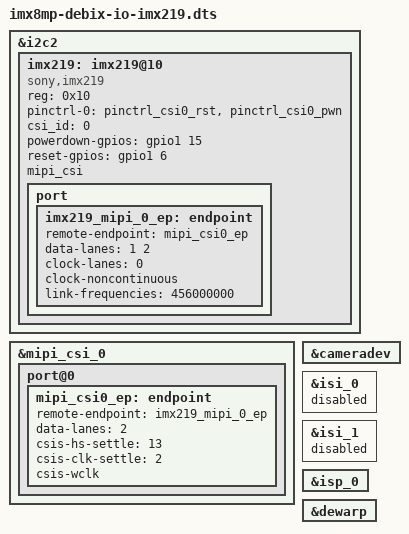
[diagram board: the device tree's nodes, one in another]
// SPDX-License-Identifier: GPL-2.0+
/*
 * Copyright 2020 NXP
 */

#include "imx8mp-debix-io-board.dts"

/delete-node/ &imx219;

&i2c2 {

	imx219: imx219@10 {
		compatible = "sony,imx219";
		reg = <0x10>;
		pinctrl-names = "default";
		pinctrl-0 = <&pinctrl_csi0_rst> ,<&pinctrl_csi0_pwn>; 

		csi_id = <0>;
		powerdown-gpios = <&gpio1 15 GPIO_ACTIVE_HIGH>;
		reset-gpios = <&gpio1 6 GPIO_ACTIVE_HIGH>;

		
		mipi_csi;
		status = "okay";
		


		port {
			imx219_mipi_0_ep: endpoint {
				remote-endpoint = <&mipi_csi0_ep>;
				data-lanes = <1 2>;
				clock-lanes = <0>;
				clock-noncontinuous;
				link-frequencies = /bits/ 64 <456000000>;
	
			};
		};
	};

};

&mipi_csi_0 { 
    
    port@0 {
        mipi_csi0_ep: endpoint {
        ///delete-property/ remote-endpoint;
	        remote-endpoint = <&imx219_mipi_0_ep>;
					data-lanes = <2>;
					csis-hs-settle = <13>;
					csis-clk-settle = <2>;
					csis-wclk;
			};
   };
};

&cameradev {

        /delete-node/ mipi_csi_1;
};

&isi_0 {
	status = "disabled";

};

&isi_1 {
	status = "disabled";

};


&isp_0 {
	status = "okay";
};

&dewarp {
	status = "okay";
};

